# IOTKit_ARMv8MBLL register map
Vendor: ARM Ltd.; Series: ARMv8-M Baseline; File version: 1.0
CPU: ARMV8MBL r0p0, little endian, MPU, no FPU, 3 interrupt priority bits, 4 SAU regions
Registers are 32-bit, read-write, reset 0x0 unless marked. A register's access mark holds for its fields unless they carry their own. Offsets are from the block's base; [hi:lo] are bit positions; {n}, {i} and the like mark numbered series.

## I2C0 — I2C 0 (Non-Secure)
Base 0x40207000
Same registers: I2C1 0x40208000, I2C2 0x4020C000, I2C3 0x4020D000, I2C0_Secure 0x50207000, I2C1_Secure 0x50208000, I2C2_Secure 0x5020C000, I2C3_Secure 0x5020D000
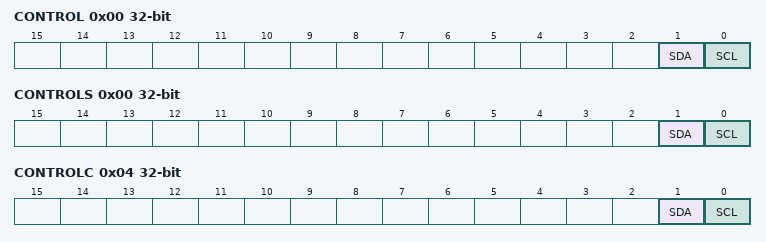
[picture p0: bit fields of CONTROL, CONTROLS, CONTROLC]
0x00 CONTROL ro — Control Status
  [1] SDA — Serial data line
  [0] SCL — Serial clock line
0x00 CONTROLS wo (alternate view of CONTROL) — Control Set
  [1] SDA — Serial data line
  [0] SCL — Serial clock line
0x04 CONTROLC wo — Control Clear
  [1] SDA — Serial data line
  [0] SCL — Serial clock line

## WATCHDOG — Watchdog Timer
Base 0x40008000
0x00 LOAD
0x04 VALUE ro
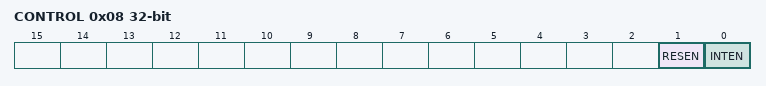
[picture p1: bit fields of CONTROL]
0x08 CONTROL
  [1] RESEN — Watchdog reset output enable
    0=Disable Watchdog reset; 1=ENable Watchdog reset
  [0] INTEN — Interrupt event enable
    0=Disable Watchdog interrupt; 1=Enable Watchdog interrupt
0x0C INTCLR wo — Interrupt Clear Register
  [0] INT write-1-clears — Interrupt
0x10 RIS ro — Raw Interrupt Status Register
  [0] RIS — Raw watchdog interrupt
0x14 MIS ro — Mask Interrupt Status Register
  [0] MIS — Masked Watchdog interrupt
0xC00 LOCK

## SCC — Serial Communication Controller
Base 0x40300000
Same registers: SCC_Secure 0x50300000
0x00 CFG_REG0 — Configuration register 0
  [0] REMAP — REMAP Block RAM to ZBT
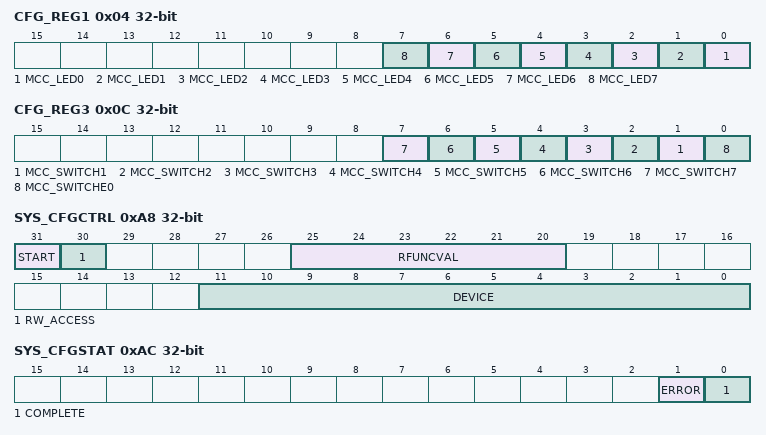
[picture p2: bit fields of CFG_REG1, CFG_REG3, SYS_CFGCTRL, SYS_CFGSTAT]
0x04 CFG_REG1 — Configuration register 1
  [all] fields
    0=Off (LED is off); 1=On (LED is on)
  [n] MCC_LED{n} (n=0..7)
0x08 CFG_REG2 ro — Configuration register 2
0x0C CFG_REG3 ro — Configuration register 3
  [all] fields
    0=Off (Switch is off); 1=On (Switch is on)
  [n] MCC_SWITCH{n} (n=1..7)
  [0] MCC_SWITCHE0 — MCC switch 0
0x10 CFG_REG4 ro — Configuration register 4
  [3:0] BRDREV — Board Revision
0x14 CFG_REG5
  [5] DEBUG — Debug connection
    0=SWD (Serial Wire Debug); 1=JTAG
0x18 CFG_REG6 ro
0x1C CFG_REG7 ro
0xA0 SYS_CFGDATA_RTN — System configuration data register RTN
0xA4 SYS_CFGDATA_OUT — System configuration data register OUT
0xA8 SYS_CFGCTRL — System configuration control register
  [31] START — Start: generates interrupt on write to this bit
  [30] RW_ACCESS — Read/Write Access
  [25:20] RFUNCVAL — Function value
  [11:0] DEVICE — Device (value of 0/1/2 for supported clocks
0xAC SYS_CFGSTAT — System configuration status register
  [1] ERROR — Error Flag
  [0] COMPLETE — Complete Flag
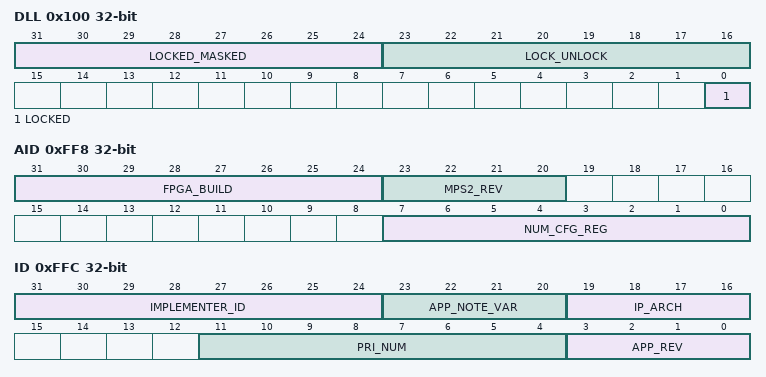
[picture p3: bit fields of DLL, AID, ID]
0x100 DLL — DLL Lock Register
  [31:24] LOCKED_MASKED — Error Flag
  [23:16] LOCK_UNLOCK — Complete Flag
  [0] LOCKED — Complete Flag
0xFF8 AID ro
  [31:24] FPGA_BUILD — FPGA Build Number
  [23:20] MPS2_REV — V2M-MPS2 target Board Revision
    0=A (Revision A); 1=B (Revision B); 2=C (Revision C)
  [7:0] NUM_CFG_REG — Number of SCC configuration register
0xFFC ID ro — AID register
  [31:24] IMPLEMENTER_ID — Implementer ID: 0x41 = ARM
    65=ARM
  [23:20] APP_NOTE_VAR — Application note IP variant number
  [19:16] IP_ARCH — IP Architecture
    4=AHB
  [11:4] PRI_NUM — Primary Part Number: 383 = AN383
  [3:0] APP_REV — Application note IP revision number

## I2S — simple audio I2S peripheral (Non-Secure)
Base 0x40301000
Same registers: I2S_Secure 0x50301000
0x00 CONTROL
0x04 STATUS ro
0x08 ERROR — Error Status Register
0x0C DIVIDE — Divide ratio Register
0x10 TXBUF wo — Transmit Buffer
0x14 RXBUF ro — Receive Buffer
0x300 ITCR — Integration Test Control Register
0x304 ITIP1 — Integration Test Input Register 1
0x308 ITOP1 — Integration Test Output Register 1

## FPGASYS — FPGA System Control I/O
Base 0x40302000
Same registers: FPGASYS_Secure 0x50302000
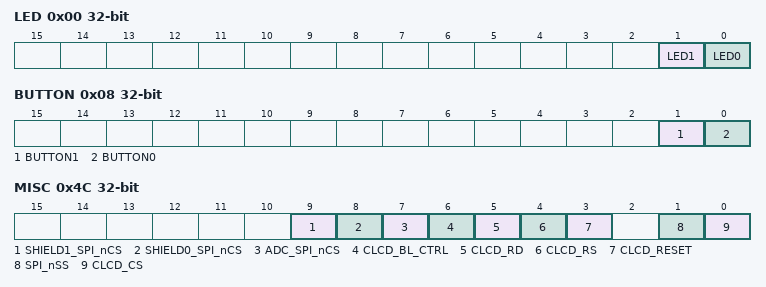
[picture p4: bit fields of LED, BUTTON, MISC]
0x00 LED — LED Connections
  [1] LED1
    0=Off (LED is off); 1=On (LED is on)
  [0] LED0
    0=Off (LED is off); 1=On (LED is on)
0x08 BUTTON — Button Connections
  [1] BUTTON1
    0=Off (BUTTON is off); 1=On (BUTTON is on)
  [0] BUTTON0
    0=Off (BUTTON is off); 1=On (BUTTON is on)
0x10 CLK1HZ ro — 1Hz Up Counter
0x14 CLK100HZ ro — 100Hz Up Counter
0x18 COUNTER — Cycle up counter
0x1C PRESCALER — Reload value for prescaler counter
0x20 PSCNTR — Prescale Counter
0x4C MISC — Misc. Control
  [9] SHIELD1_SPI_nCS, [8] SHIELD0_SPI_nCS, [7] ADC_SPI_nCS, [6] CLCD_BL_CTRL, [5] CLCD_RD, [4] CLCD_RS, [3] CLCD_RESET, [1] SPI_nSS, [0] CLCD_CS

## MPC_SSRAM1 — Memory Protection Controller SSRAM1
Base 0x58007000
Same registers: MPC_SSRAM2 0x58008000, MPC_SSRAM3 0x58009000
0x00 CTRL — Control Register
0x10 BLK_MAX ro — Block Maximum Register
0x14 BLK_CFG ro — Block Configuration Register
0x18 BLK_IDX — Block Index Register
0x1C BLK_LUT — Block Lookup Tabe Register
0x20 INT_STAT ro — Interrupt Status Register
0x24 INT_CLEAR wo — Interrupt Clear Register
0x28 INT_EN — Interrupt Enable Register
0x2C INT_INFO1 ro — Interrupt Info1 Register
0x30 INT_INFO2 ro — Interrupt Info2 Register
0x34 INT_SET wo — Interrupt Set Register

## SPC — Secure Privilege Control Block
Base 0x50080000
0x10 SECRESPCFG — Security Violation Response Configuration Register
0x14 NSCCFG — Non Secure Callable Configuration for IDAU
0x1C SECMPCINTSTATUS ro — Secure MPC Interrupt Status
0x20 SECPPCINTSTAT ro — Secure PPC Interrupt Status
0x24 SECPPCINTCLR wo — Secure PPC Interrupt Clear
0x28 SECPPCINTEN — Secure PPC Interrupt Enable
0x30 SECMSCINTSTAT ro — Secure MSC Interrupt Status
0x34 SECMSCINTCLR wo — Secure MSC Interrupt Clear
0x38 SECMSCINTEN — Secure MSC Interrupt Enable
0x40 BRGINTSTAT ro — Bridge Buffer Error Interrupt Status
0x44 BRGINTCLR wo — Bridge Buffer Error Interrupt Clear
0x48 BRGINTEN — Bridge Buffer Error Interrupt Enable
{0x50+4i} AHBNSPPC[{i}] (i=0..3) — Non-Secure Access AHB slave Peripheral Protection Control
{0x60+4i} AHBNSPPCEXP[{i}] (i=0..3) — Expansion Non_Secure Access AHB slave Peripheral Protection Control
{0x70+4i} APBNSPPC[{i}] (i=0..3) — Non-Secure Access APB slave Peripheral Protection Control
{0x80+4i} APBNSPPCEXP[{i}] (i=0..3) — Expansion Non_Secure Access APB slave Peripheral Protection Control
{0x90+4i} AHBSPPPC[{i}] (i=0..3) ro — Secure Unprivileged Access AHB slave Peripheral Protection Control
{0xA0+4i} AHBSPPPCEXP[{i}] (i=0..3) — Expansion Secure Unprivileged Access AHB slave Peripheral Protection Control
{0xB0+4i} APBSPPPC[{i}] (i=0..3) — Secure Unprivileged Access APB slave Peripheral Protection Control
{0xC0+4i} APBSPPPCEXP[{i}] (i=0..3) — Expansion Secure Unprivileged Access APB slave Peripheral Protection Control
0xD0 NSMSCEXP ro — Expansion MSC Non-Secure Configuration

## NSPC — Non-Secure Privilege Control Block
Base 0x40080000
{0x90+4i} AHBNSPPPC[{i}] (i=0..3) — Non-Secure Unprivileged Access AHB slave Peripheral Protection Control
{0xA0+4i} AHBNSPPPCEXP[{i}] (i=0..3) — Expansion 0 Non-Secure Unprivileged Access AHB slave Peripheral Protection Control
{0xB0+4i} APBNSPPPC[{i}] (i=0..3) — Non-Secure Unprivileged Access APB slave Peripheral Protection Control
{0xC0+4i} APBNSPPPCEXP[{i}] (i=0..3) — Expansion 0 Non-Secure Unprivileged Access APB slave Peripheral Protection Control

## DEBUG
Base 0x50007000
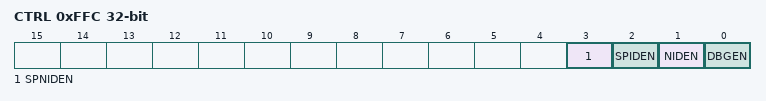
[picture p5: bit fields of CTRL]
0xFFC CTRL
  [3] SPNIDEN — Secure Non Invasive Debug
  [2] SPIDEN — Secure Debug Enable
  [1] NIDEN — Non-intrusive debug enable
  [0] DBGEN — Debug enable (must be 1 to debug)
